AUTOSAR XML (schema 4-2-2)
package /ETAS_BIP
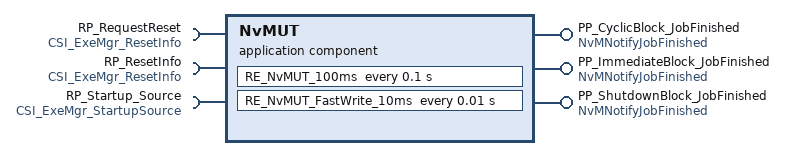
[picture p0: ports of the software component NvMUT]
  application sw component type NvMUT
    provide/require port PRP_CyclicNvBlock: provided-required-interface=SRI_CyclicNvBlock_ArrayU8_1024
    provide/require port PRP_ShutdownNvBlock: provided-required-interface=SRI_ShutDownNvBlock_ArrayBoolean_96
    provide port PP_CyclicBlock_JobFinished: provided-interface=NvMNotifyJobFinished
    provide port PP_ImmediateBlock_JobFinished: provided-interface=NvMNotifyJobFinished
    provide port PP_ShutdownBlock_JobFinished: provided-interface=NvMNotifyJobFinished
    provide/require port PRP_ImmediateNvBlock: provided-required-interface=SRI_ImmediateNvBlock_ArrayU32_96
    require port RP_RequestReset: required-interface=CSI_ExeMgr_ResetInfo
    require port RP_ResetInfo: required-interface=CSI_ExeMgr_ResetInfo
    provide/require port PRP_Fast_ImmediateNvBlock: provided-required-interface=SRI_ImmediateNvBlock_ArrayU32_96
    require port RP_Startup_Source: required-interface=CSI_ExeMgr_StartupSource
    behavior IB_NvMUT: data-type-mapping=DTMS_NvBlockDirtyFlag
      timing event TE_NvMUT_100ms: start-on-event=RE_NvMUT_100ms, period=0.1
      operation invoked event OIE_ImmediateBlock_JobFinished: start-on-event=RE_ImmdiateBlock_JobFinished, operation=PP_ImmediateBlock_JobFinished.JobFinished
      operation invoked event OIE_ShutdownBlock_JobFinished: start-on-event=RE_ShutdownBlock_JobFinished, operation=PP_ShutdownBlock_JobFinished.JobFinished
      operation invoked event OIE_CyclicBlock_JobFinished: start-on-event=RE_CyclicBlock_JobFinished, operation=PP_CyclicBlock_JobFinished.JobFinished
      timing event TE_NvFW_10ms: start-on-event=RE_NvMUT_FastWrite_10ms, period=0.01
      5 x runnable:
        RE_NvMUT_100ms
          data-receive-point-by-arguments:
            access DRPA_CyclicNvBlock_0: accessed-variable=PRP_CyclicNvBlock.CyclicNvBlock
            access DRPA_ShutDownNvBlock_0: accessed-variable=PRP_ShutdownNvBlock.ShutDownNvBlock
            access DRPA_ImmediateNvBlock_0: accessed-variable=PRP_ImmediateNvBlock.ImmediateNvBlock
          data-send-points:
            access DSP_ShutDownNvBlock_0: accessed-variable=PRP_ShutdownNvBlock.ShutDownNvBlock
            access DSP_CyclicNvBlock_0: accessed-variable=PRP_CyclicNvBlock.CyclicNvBlock
            access DSP_ImmediateNvBlock_0: accessed-variable=PRP_ImmediateNvBlock.ImmediateNvBlock
          sync call SynchronousServerCallPoint_0: operation=RP_RequestReset.RequestReset
          sync call SynchronousServerCallPoint_1: operation=RP_ResetInfo.GetLastResetInfo
          sync call SynchronousServerCallPoint: operation=RP_Startup_Source.GetLastStartupSource
        RE_CyclicBlock_JobFinished
        RE_ImmdiateBlock_JobFinished
        RE_ShutdownBlock_JobFinished
        RE_NvMUT_FastWrite_10ms
